# LargeDummyDevice register map
File version: 1.0
Registers are 32-bit, read-write, no defined reset value unless marked. A register's access mark holds for its fields unless they carry their own. Offsets are from the block's base; [hi:lo] are bit positions.

## PERIPHERAL_56
Base 0x40037000
0x04 REG_1 — Register 1
  [32:31] FIELD_1, [29:27] FIELD_12, [24:20] FIELD_16, [21:19] FIELD_2, [22:19] FIELD_11, [18:16] FIELD_7, [17:15] FIELD_4, [16:15] FIELD_9, [13:12] FIELD_3, [16:12] FIELD_8, [14:10] FIELD_13, [11:8] FIELD_17, [8:5] FIELD_6, [7:4] FIELD_15, [3:2] FIELD_5, [2:1] FIELD_10, [4:0] FIELD_14, [3:0] FIELD_18
0x08 REG_2 — Register 2
  [32:31] FIELD_4, [29:28] FIELD_22, [27] FIELD_16, [25:24] FIELD_2, [26:23] FIELD_15, [21] FIELD_1, [21] FIELD_18, [24:20] FIELD_5, [20] FIELD_21, [23:19] FIELD_9, [21:19] FIELD_12, [19:17] FIELD_3, [16:15] FIELD_6, [18:15] FIELD_14, [15] FIELD_17, [13] FIELD_13, [16:12] FIELD_8, [12] FIELD_10, [10:8] FIELD_11, [6] FIELD_20, [8:5] FIELD_7, [5:1] FIELD_19
0x0C REG_3 — Register 3
  [30:27] FIELD_1, [28:27] FIELD_17, [30:26] FIELD_7, [27:26] FIELD_12, [27:24] FIELD_4, [25:23] FIELD_2, [21:20] FIELD_16, [18:16] FIELD_8, [15] FIELD_15, [13:12] FIELD_13, [14:11] FIELD_5, [10] FIELD_3, [10:8] FIELD_9, [11:7] FIELD_10, [9:7] FIELD_11, [6:4] FIELD_6, [4:0] FIELD_14
0x10 REG_4 — Register 4
  [27:24] FIELD_6, [23:22] FIELD_7, [23:21] FIELD_2, [24:20] FIELD_3, [19] FIELD_5, [9:7] FIELD_1, [6:5] FIELD_4
0x14 REG_5 — Register 5
  [22] FIELD_8, [24:21] FIELD_4, [22:18] FIELD_1, [19:17] FIELD_2, [12:9] FIELD_3, [12:8] FIELD_12, [8:7] FIELD_9, [6:5] FIELD_6, [4:2] FIELD_5, [5:1] FIELD_11, [1:0] FIELD_7, [0] FIELD_10
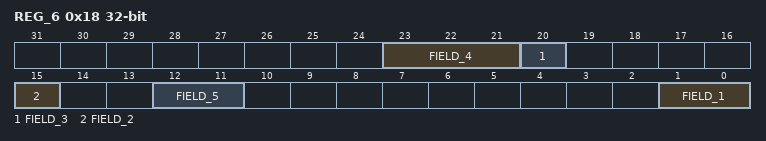
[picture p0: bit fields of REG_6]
0x18 REG_6 — Register 6
  [23:21] FIELD_4, [20] FIELD_3, [15] FIELD_2, [12:11] FIELD_5, [1:0] FIELD_1
0x1C REG_7 — Register 7
  [31:30] FIELD_7, [31:29] FIELD_1, [29] FIELD_19, [30:27] FIELD_20, [28:25] FIELD_14, [26:24] FIELD_12, [24:23] FIELD_9, [27:23] FIELD_18, [25:22] FIELD_4, [25:21] FIELD_16, [22:21] FIELD_17, [18:17] FIELD_11, [15:12] FIELD_3, [14:12] FIELD_6, [14:11] FIELD_21, [11:10] FIELD_5, [12:9] FIELD_15, [11:8] FIELD_10, [8:6] FIELD_8, [7:5] FIELD_13, [5:3] FIELD_2, [4:3] FIELD_22, [7:3] FIELD_23
0x20 REG_8 — Register 8
  [22:18] FIELD_1

## PERIPHERAL_60
Base 0x4003B000
0x04 REG_1 — Register 1
  [35:31] FIELD_7, [31:30] FIELD_3, [31:29] FIELD_1, [32:28] FIELD_11, [29:26] FIELD_18, [25:24] FIELD_21, [26:23] FIELD_4, [20:19] FIELD_17, [17:16] FIELD_12, [15:14] FIELD_5, [15:12] FIELD_8, [12] FIELD_9, [12:11] FIELD_20, [10] FIELD_16, [11:9] FIELD_15, [11:7] FIELD_14, [7:5] FIELD_10, [5:2] FIELD_13, [3:2] FIELD_19, [4:1] FIELD_2, [3:1] FIELD_6

## PERIPHERAL_66
Base 0x40041000
0x04 REG_1 — Register 1
  [30:29] FIELD_12, [32:28] FIELD_11, [28:27] FIELD_22, [26] FIELD_14, [27:24] FIELD_13, [25:23] FIELD_8, [24:21] FIELD_7, [24:21] FIELD_10, [23:21] FIELD_16, [24:21] FIELD_18, [23:20] FIELD_9, [22:19] FIELD_20, [18] FIELD_3, [19:18] FIELD_21, [17] FIELD_6, [17:16] FIELD_5, [15:14] FIELD_17, [11:8] FIELD_15, [9:6] FIELD_1, [6] FIELD_4, [7:4] FIELD_2, [7:3] FIELD_19
0x08 REG_2 — Register 2
  [32:31] FIELD_10, [32:28] FIELD_9, [19:18] FIELD_2, [14:13] FIELD_4, [13:10] FIELD_5, [13:9] FIELD_7, [10:7] FIELD_11, [7:5] FIELD_3, [7:5] FIELD_8, [6:4] FIELD_1, [2:0] FIELD_6
0x0C REG_3 — Register 3
  [33:31] FIELD_8, [29:26] FIELD_1, [26:25] FIELD_3, [27:25] FIELD_5, [26:23] FIELD_4, [24:22] FIELD_6, [13:9] FIELD_7, [5:2] FIELD_2, [1] FIELD_9, [4:0] FIELD_10
0x10 REG_4 — Register 4
  [31:29] FIELD_1, [29:28] FIELD_2, [30:28] FIELD_3, [25] FIELD_12, [25:24] FIELD_7, [23] FIELD_10, [25:23] FIELD_17, [24:21] FIELD_20, [23:19] FIELD_5, [20:18] FIELD_15, [20:16] FIELD_8, [17:16] FIELD_16, [16:15] FIELD_4, [14] FIELD_6, [18:14] FIELD_14, [14:13] FIELD_19, [12] FIELD_11, [14:10] FIELD_18, [8:7] FIELD_13, [3] FIELD_9
0x14 REG_5 — Register 5
  [33:29] FIELD_4, [17:14] FIELD_3, [13] FIELD_2, [12:9] FIELD_1, [13:9] FIELD_5, [6] FIELD_6
